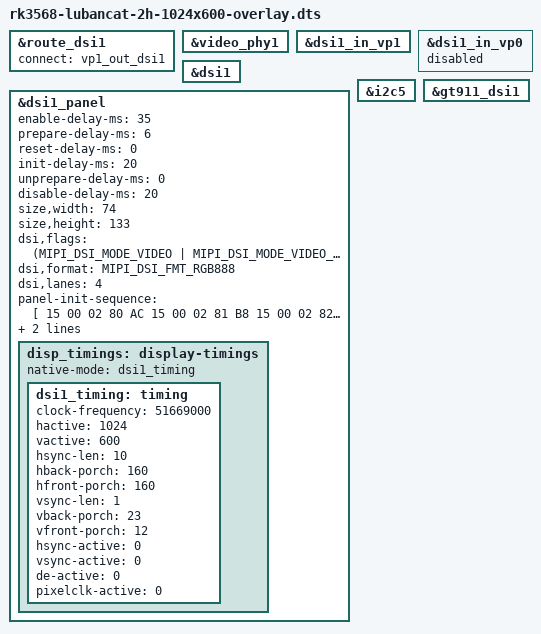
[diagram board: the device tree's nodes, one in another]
/dts-v1/;
/plugin/;

#include <dt-bindings/gpio/gpio.h>
#include <dt-bindings/pinctrl/rockchip.h>
#include <dt-bindings/display/drm_mipi_dsi.h>
#include <dt-bindings/interrupt-controller/irq.h>

/ {

	fragment@0 {
		target = <&route_dsi1>;

		__overlay__ {
			status = "okay";
			connect = <&vp1_out_dsi1>;
		};
	};

	fragment@1 {
		target = <&video_phy1>;

		__overlay__ {
			status = "okay";
		};
	};

	fragment@2 {
		target = <&dsi1_in_vp1>;

		__overlay__ {
			status = "okay";
		};
	};

	fragment@3 {
		target = <&dsi1_in_vp0>;

		__overlay__ {
			status = "disabled";
		};
	};

	fragment@4 {
		target = <&dsi1>;

		__overlay__ {
			status = "okay";
		};
	};

	fragment@5 {
		target = <&dsi1_panel>;

		__overlay__ {
			status = "okay";

			enable-delay-ms = <35>;
			prepare-delay-ms = <6>;
			reset-delay-ms = <0>;
			init-delay-ms = <20>;
			unprepare-delay-ms = <0>;
			disable-delay-ms = <20>;

			size,width = <74>;
			size,height = <133>;

			dsi,flags = <(MIPI_DSI_MODE_VIDEO | MIPI_DSI_MODE_VIDEO_BURST | MIPI_DSI_MODE_LPM | MIPI_DSI_MODE_EOT_PACKET)>;
			dsi,format = <MIPI_DSI_FMT_RGB888>;
			dsi,lanes  = <4>;

			panel-init-sequence = [
				15 00 02 80 AC
				15 00 02 81 B8
				15 00 02 82 09
				15 00 02 83 78
				15 00 02 84 7f
				15 00 02 85 bb
				15 00 02 86 70
			];

			panel-exit-sequence = [
				05 78 01 28
				05 00 01 10
			];

			disp_timings: display-timings {
				native-mode = <&dsi1_timing>;
				dsi1_timing: timing {
					clock-frequency = <51669000>;
					hactive = <1024>;
					vactive = <600>;
					hsync-len = <10>;
					hback-porch = <160>;
					hfront-porch = <160>;
					vsync-len = <1>;
					vback-porch = <23>;
					vfront-porch = <12>;
					hsync-active = <0>;
					vsync-active = <0>;
					de-active = <0>;
					pixelclk-active = <0>;
				};
			};
		};
	};

	fragment@6 {
		target = <&i2c5>;

		__overlay__ {
			status = "okay";
		};
	};

	fragment@7 {
		target = <&gt911_dsi1>;

		__overlay__ {
			status = "okay";
		};
	};
};
